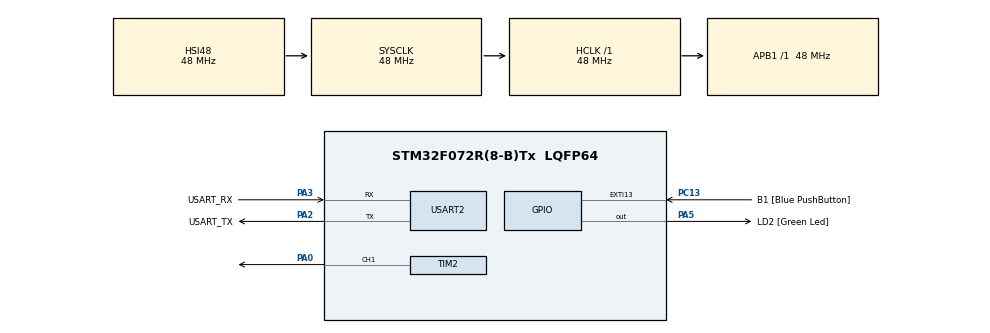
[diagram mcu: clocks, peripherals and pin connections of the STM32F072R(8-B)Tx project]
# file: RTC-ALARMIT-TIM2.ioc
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Mcu.Family=STM32F0
Mcu.Name=STM32F072R(8-B)Tx
Mcu.Package=LQFP64
NVIC.RTC_IRQn=true\:0\:0\:false\:false\:true\:true\:true\:true
NVIC.TIM2_IRQn=true\:0\:0\:false\:false\:true\:true\:true\:true
PA0.Signal=S_TIM2_CH1_ETR
PA13.GPIO_Label=TMS
PA13.Mode=Serial_Wire
PA13.Signal=SYS_SWDIO
PA14.GPIO_Label=TCK
PA14.Mode=Serial_Wire
PA14.Signal=SYS_SWCLK
PA2.GPIO_Label=USART_TX
PA2.GPIO_Mode=GPIO_MODE_AF_PP
PA2.GPIO_PuPd=GPIO_NOPULL
PA2.GPIO_Speed=GPIO_SPEED_FREQ_LOW
PA2.Mode=Asynchronous
PA2.Signal=USART2_TX
PA3.GPIO_Label=USART_RX
PA3.GPIO_Mode=GPIO_MODE_AF_PP
PA3.GPIO_PuPd=GPIO_NOPULL
PA3.GPIO_Speed=GPIO_SPEED_FREQ_LOW
PA3.Mode=Asynchronous
PA3.Signal=USART2_RX
PA5.GPIO_Label=LD2 [Green Led]
PA5.GPIO_Mode=GPIO_MODE_OUTPUT_PP
PA5.GPIO_PuPd=GPIO_NOPULL
PA5.GPIO_Speed=GPIO_SPEED_FREQ_LOW
PA5.Signal=GPIO_Output
PC13.GPIO_Label=B1 [Blue PushButton]
PC13.GPIO_ModeDefaultEXTI=GPIO_MODE_IT_FALLING
PC13.Signal=GPXTI13
PC14-OSC32_IN.Mode=LSE-External-Oscillator
PC14-OSC32_IN.Signal=RCC_OSC32_IN
PC15-OSC32_OUT.Mode=LSE-External-Oscillator
PC15-OSC32_OUT.Signal=RCC_OSC32_OUT
PF0-OSC_IN.Mode=HSE-External-Clock-Source
PF0-OSC_IN.Signal=RCC_OSC_IN
PF1-OSC_OUT.Signal=RCC_OSC_OUT
ProjectManager.HeapSize=0x200
ProjectManager.StackSize=0x400
ProjectManager.TargetToolchain=STM32CubeIDE
RCC.AHBFreq_Value=48000000
RCC.APB1Freq_Value=48000000
RCC.APB1TimFreq_Value=48000000
RCC.FLatency-AdvancedSettings=FLASH_LATENCY_1
RCC.HCLKFreq_Value=48000000
RCC.PLLDivider=RCC_PREDIV_DIV2
RCC.PLLMUL=RCC_PLL_MUL12
RCC.PREFETCH_ENABLE-AdvancedSettings=1
RCC.SYSCLKFreq_VALUE=48000000
RCC.SYSCLKSource=RCC_SYSCLKSOURCE_HSI48
RTC.Alarm-Alarm\ A=RTC_ALARM_A
RTC.Date=1
RTC.Format=RTC_FORMAT_BIN
RTC.Hours=7
RTC.Hours_A-Alarm\ A=8
RTC.Minutes=59
RTC.Seconds=50
RTC.Year=24
SH.S_TIM2_CH1_ETR.0=TIM2_CH1,Output Compare1 CH1
TIM2.Channel-Output\ Compare1\ CH1=TIM_CHANNEL_1
USART2.VirtualMode=VM_ASYNC
USART2.VirtualMode-Asynchronous=VM_ASYNC
VP_RTC_VS_RTC_Activate.Mode=RTC_Enabled
VP_RTC_VS_RTC_Alarm_A_Intern.Mode=Alarm A
VP_RTC_VS_RTC_Calendar.Mode=RTC_Calendar
VP_TIM2_VS_ClockSourceINT.Mode=Internal
board=NUCLEO-F072RB

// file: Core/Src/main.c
/* USER CODE BEGIN Header */
/**
  ******************************************************************************
  * @file           : main.c
  * @brief          : Main program body
  ******************************************************************************
  * @attention
  *
  * Copyright (c) 2024 STMicroelectronics.
  * All rights reserved.
  *
  * This software is licensed under terms that can be found in the LICENSE file
  * in the root directory of this software component.
  * If no LICENSE file comes with this software, it is provided AS-IS.
  *
  ******************************************************************************
  */
/* USER CODE END Header */
#include "main.h"

/* USER CODE BEGIN Includes */
#include <string.h>
#include <stdint.h>
#include <stdarg.h>
#include <stdio.h>
/* USER CODE END Includes */

RTC_HandleTypeDef hrtc;

TIM_HandleTypeDef htim2;

UART_HandleTypeDef huart2;

/* USER CODE BEGIN PV */
RTC_TimeTypeDef RTC_TimeRead;
RTC_DateTypeDef RTC_DateRead;
/* USER CODE END PV */

void SystemClock_Config(void);
static void MX_GPIO_Init(void);
static void MX_USART2_UART_Init(void);
static void MX_RTC_Init(void);
static void MX_TIM2_Init(void);
/* USER CODE BEGIN PFP */
void printmsg(char *format,...);   //Print function prototype

/* USER CODE END PFP */

/* USER CODE BEGIN 0 */
uint32_t CCR_content;             //The value to Compare for TIM6 interrupt event
/* USER CODE END 0 */

int main(void)
{

  /* MCU Configuration--------------------------------------------------------*/

  /* Reset of all peripherals, Initializes the Flash interface and the Systick. */
  HAL_Init();

  /* Configure the system clock */
  SystemClock_Config();

  /* Initialize all configured peripherals */
  MX_GPIO_Init();
  MX_USART2_UART_Init();
  MX_RTC_Init();
  MX_TIM2_Init();
  /* USER CODE BEGIN 2 */

//HAL_NVIC_SetPriority(TIM6_IRQn, 0, 0);

  /* USER CODE END 2 */

  /* Infinite loop */
  while (1)
  {

  }

}

void SystemClock_Config(void)
{
  RCC_OscInitTypeDef RCC_OscInitStruct = {0};
  RCC_ClkInitTypeDef RCC_ClkInitStruct = {0};
  RCC_PeriphCLKInitTypeDef PeriphClkInit = {0};

  /** Initializes the RCC Oscillators according to the specified parameters
  * in the RCC_OscInitTypeDef structure.
  */
  RCC_OscInitStruct.OscillatorType = RCC_OSCILLATORTYPE_HSI48|RCC_OSCILLATORTYPE_LSI;
  RCC_OscInitStruct.HSI48State = RCC_HSI48_ON;
  RCC_OscInitStruct.LSIState = RCC_LSI_ON;
  RCC_OscInitStruct.PLL.PLLState = RCC_PLL_NONE;
  if (HAL_RCC_OscConfig(&RCC_OscInitStruct) != HAL_OK)
  {
    Error_Handler();
  }

  /** Initializes the CPU, AHB and APB buses clocks
  */
  RCC_ClkInitStruct.ClockType = RCC_CLOCKTYPE_HCLK|RCC_CLOCKTYPE_SYSCLK
                              |RCC_CLOCKTYPE_PCLK1;
  RCC_ClkInitStruct.SYSCLKSource = RCC_SYSCLKSOURCE_HSI48;
  RCC_ClkInitStruct.AHBCLKDivider = RCC_SYSCLK_DIV1;
  RCC_ClkInitStruct.APB1CLKDivider = RCC_HCLK_DIV1;

  if (HAL_RCC_ClockConfig(&RCC_ClkInitStruct, FLASH_LATENCY_1) != HAL_OK)
  {
    Error_Handler();
  }
  PeriphClkInit.PeriphClockSelection = RCC_PERIPHCLK_USART2|RCC_PERIPHCLK_RTC;
  PeriphClkInit.Usart2ClockSelection = RCC_USART2CLKSOURCE_PCLK1;
  PeriphClkInit.RTCClockSelection = RCC_RTCCLKSOURCE_LSI;
  if (HAL_RCCEx_PeriphCLKConfig(&PeriphClkInit) != HAL_OK)
  {
    Error_Handler();
  }
}

static void MX_RTC_Init(void)
{

  RTC_TimeTypeDef sTime = {0};
  RTC_DateTypeDef sDate = {0};
  RTC_AlarmTypeDef sAlarm = {0};

  /** Initialize RTC Only
  */
  hrtc.Instance = RTC;
  hrtc.Init.HourFormat = RTC_HOURFORMAT_24;
  hrtc.Init.AsynchPrediv = 127;
  hrtc.Init.SynchPrediv = 255;
  hrtc.Init.OutPut = RTC_OUTPUT_DISABLE;
  hrtc.Init.OutPutPolarity = RTC_OUTPUT_POLARITY_HIGH;
  hrtc.Init.OutPutType = RTC_OUTPUT_TYPE_OPENDRAIN;
  if (HAL_RTC_Init(&hrtc) != HAL_OK)
  {
    Error_Handler();
  }

  /** Initialize RTC and set the Time and Date
   *
   * Initialized clock and date values at the start
  */
  sTime.Hours = 7;
  sTime.Minutes = 59;
  sTime.Seconds = 50;
  sTime.DayLightSaving = RTC_DAYLIGHTSAVING_NONE;
  sTime.StoreOperation = RTC_STOREOPERATION_RESET;
  if (HAL_RTC_SetTime(&hrtc, &sTime, RTC_FORMAT_BIN) != HAL_OK)
  {
    Error_Handler();
  }

  sDate.WeekDay = RTC_WEEKDAY_MONDAY;
  sDate.Month = RTC_MONTH_JANUARY;
  sDate.Date = 1;
  sDate.Year = 24;

  if (HAL_RTC_SetDate(&hrtc, &sDate, RTC_FORMAT_BIN) != HAL_OK)
  {
    Error_Handler();
  }

  /** Enable the Alarm A
  */
  sAlarm.AlarmTime.Hours = 8;
  sAlarm.AlarmTime.Minutes = 00;
  sAlarm.AlarmTime.Seconds = 00;
  sAlarm.AlarmTime.SubSeconds = 0;
  sAlarm.AlarmTime.DayLightSaving = RTC_DAYLIGHTSAVING_NONE;
  sAlarm.AlarmTime.StoreOperation = RTC_STOREOPERATION_RESET;
  sAlarm.AlarmMask = RTC_ALARMMASK_NONE;
  sAlarm.AlarmSubSecondMask = RTC_ALARMSUBSECONDMASK_ALL;
  sAlarm.AlarmDateWeekDaySel = RTC_ALARMDATEWEEKDAYSEL_DATE;
  sAlarm.AlarmDateWeekDay = 1;
  sAlarm.Alarm = RTC_ALARM_A;
  if (HAL_RTC_SetAlarm_IT(&hrtc, &sAlarm, RTC_FORMAT_BIN) != HAL_OK)
  {
    Error_Handler();
  }

}

static void MX_TIM2_Init(void)
{

  TIM_ClockConfigTypeDef sClockSourceConfig = {0};
  TIM_MasterConfigTypeDef sMasterConfig = {0};
  TIM_OC_InitTypeDef sConfigOC = {0};

  htim2.Instance = TIM2;
  htim2.Init.Prescaler = 1;
  htim2.Init.CounterMode = TIM_COUNTERMODE_UP;
  htim2.Init.Period = 4294967295;
  htim2.Init.ClockDivision = TIM_CLOCKDIVISION_DIV1;
  htim2.Init.AutoReloadPreload = TIM_AUTORELOAD_PRELOAD_DISABLE;
  if (HAL_TIM_Base_Init(&htim2) != HAL_OK)
  {
    Error_Handler();
  }
  sClockSourceConfig.ClockSource = TIM_CLOCKSOURCE_INTERNAL;
  if (HAL_TIM_ConfigClockSource(&htim2, &sClockSourceConfig) != HAL_OK)
  {
    Error_Handler();
  }
  if (HAL_TIM_OC_Init(&htim2) != HAL_OK)
  {
    Error_Handler();
  }
  sMasterConfig.MasterOutputTrigger = TIM_TRGO_RESET;
  sMasterConfig.MasterSlaveMode = TIM_MASTERSLAVEMODE_DISABLE;
  if (HAL_TIMEx_MasterConfigSynchronization(&htim2, &sMasterConfig) != HAL_OK)
  {
    Error_Handler();
  }
  /*
   * Initiliaze for 500HZ signal
   */
  sConfigOC.OCMode = TIM_OCMODE_TOGGLE;
  sConfigOC.Pulse = 24000;
  sConfigOC.OCPolarity = TIM_OCPOLARITY_HIGH;
  sConfigOC.OCFastMode = TIM_OCFAST_DISABLE;
  if (HAL_TIM_OC_ConfigChannel(&htim2, &sConfigOC, TIM_CHANNEL_1) != HAL_OK)
  {
    Error_Handler();
  }

  /* USER CODE END TIM2_Init 2 */
  HAL_TIM_MspPostInit(&htim2);

}

static void MX_USART2_UART_Init(void)
{

  huart2.Instance = USART2;
  huart2.Init.BaudRate = 38400;
  huart2.Init.WordLength = UART_WORDLENGTH_8B;
  huart2.Init.StopBits = UART_STOPBITS_1;
  huart2.Init.Parity = UART_PARITY_NONE;
  huart2.Init.Mode = UART_MODE_TX_RX;
  huart2.Init.HwFlowCtl = UART_HWCONTROL_NONE;
  huart2.Init.OverSampling = UART_OVERSAMPLING_16;
  huart2.Init.OneBitSampling = UART_ONE_BIT_SAMPLE_DISABLE;
  huart2.AdvancedInit.AdvFeatureInit = UART_ADVFEATURE_NO_INIT;
  if (HAL_UART_Init(&huart2) != HAL_OK)
  {
    Error_Handler();
  }
}

static void MX_GPIO_Init(void)
{
  GPIO_InitTypeDef GPIO_InitStruct = {0};

  /* GPIO Ports Clock Enable */
  __HAL_RCC_GPIOC_CLK_ENABLE();
  __HAL_RCC_GPIOF_CLK_ENABLE();
  __HAL_RCC_GPIOA_CLK_ENABLE();

  /*Configure GPIO pin Output Level */
  HAL_GPIO_WritePin(LD2_GPIO_Port, LD2_Pin, GPIO_PIN_RESET);

  /*Configure GPIO pin : B1_Pin */
  GPIO_InitStruct.Pin = B1_Pin;
  GPIO_InitStruct.Mode = GPIO_MODE_IT_FALLING;
  GPIO_InitStruct.Pull = GPIO_NOPULL;
  HAL_GPIO_Init(B1_GPIO_Port, &GPIO_InitStruct);

  /*Configure GPIO pin : LD2_Pin */
  GPIO_InitStruct.Pin = LD2_Pin;
  GPIO_InitStruct.Mode = GPIO_MODE_OUTPUT_PP;
  GPIO_InitStruct.Pull = GPIO_NOPULL;
  GPIO_InitStruct.Speed = GPIO_SPEED_FREQ_LOW;
  HAL_GPIO_Init(LD2_GPIO_Port, &GPIO_InitStruct);

/* USER CODE BEGIN MX_GPIO_Init_2 */
  /*
   * Set NVIC for B1 Interrupt!!!
   */
  HAL_NVIC_SetPriority(EXTI4_15_IRQn, 0, 0);
  HAL_NVIC_EnableIRQ(EXTI4_15_IRQn);

/* USER CODE END MX_GPIO_Init_2 */
}

/*
 * To print data use this function
 */
void printmsg(char *format,...)
{
char str[80];

va_list args;            //Extract the argument list using VA API's
va_start(args, format);
vsprintf(str, format, args);
HAL_UART_Transmit(&huart2, (uint8_t*)str, strlen(str), HAL_MAX_DELAY);
va_end(args);
}
/*
 * Turn integer day values to words
 */
char* getDayofweek(uint8_t number)
{
	char *weekday[] = { "Monday", "TuesDay", "Wednesday","Thursday","Friday","Saturday","Sunday"};

		return weekday[number-1];
}
/* USER CODE BEGIN 4 */
/*
 * When the button is pressed stop compare therefore the buzzer and reset the LD2
 */
void HAL_GPIO_EXTI_Callback(uint16_t GPIO_Pin)
{

	if(HAL_TIM_OC_Stop_IT(&htim2, TIM_CHANNEL_1)  != HAL_OK)
	{
		Error_Handler();
	}

	HAL_GPIO_WritePin(GPIOA, GPIO_PIN_5, GPIO_PIN_RESET);

}
/*
 * Form a constant 500HZ freq signal to PA0 port
 */
void HAL_TIM_OC_DelayElapsedCallback(TIM_HandleTypeDef *htim)
{

	if (htim->Channel == HAL_TIM_ACTIVE_CHANNEL_1)
	{
	   CCR_content = HAL_TIM_ReadCapturedValue(htim, TIM_CHANNEL_1);
	   __HAL_TIM_SET_COMPARE(htim, TIM_CHANNEL_1, CCR_content + 24000);
	   HAL_GPIO_TogglePin(GPIOA, GPIO_PIN_0);
	}

}

/*
 * With the RTC event Print date and time on UART and start Buzzer signal
 */
void HAL_RTC_AlarmAEventCallback(RTC_HandleTypeDef *hrtc)
{
	printmsg("Alarm Triggered \r\n");

	HAL_RTC_GetTime(hrtc, &RTC_TimeRead, RTC_FORMAT_BIN);
	HAL_RTC_GetDate(hrtc, &RTC_DateRead, RTC_FORMAT_BIN); //Tou should write GetDate after time for not to encouter problems

	printmsg("Getting RTC time\n");

	printmsg("Current Time is : %02d:%02d:%02d\r\n", RTC_TimeRead.Hours,
			RTC_TimeRead.Minutes, RTC_TimeRead.Seconds);
	printmsg("Current Date is : %02d-%2d-%2d  <%s> \r\n", RTC_DateRead.Month,
			RTC_DateRead.Date, RTC_DateRead.Year,
			getDayofweek(RTC_DateRead.WeekDay));

	HAL_GPIO_WritePin(GPIOA, GPIO_PIN_5, GPIO_PIN_SET);

	if(HAL_TIM_OC_Start_IT(&htim2, TIM_CHANNEL_1)  != HAL_OK)
	{
		Error_Handler();
	}
}

void Error_Handler(void)
{
  __disable_irq();
  while (1)
  {
  }
}
